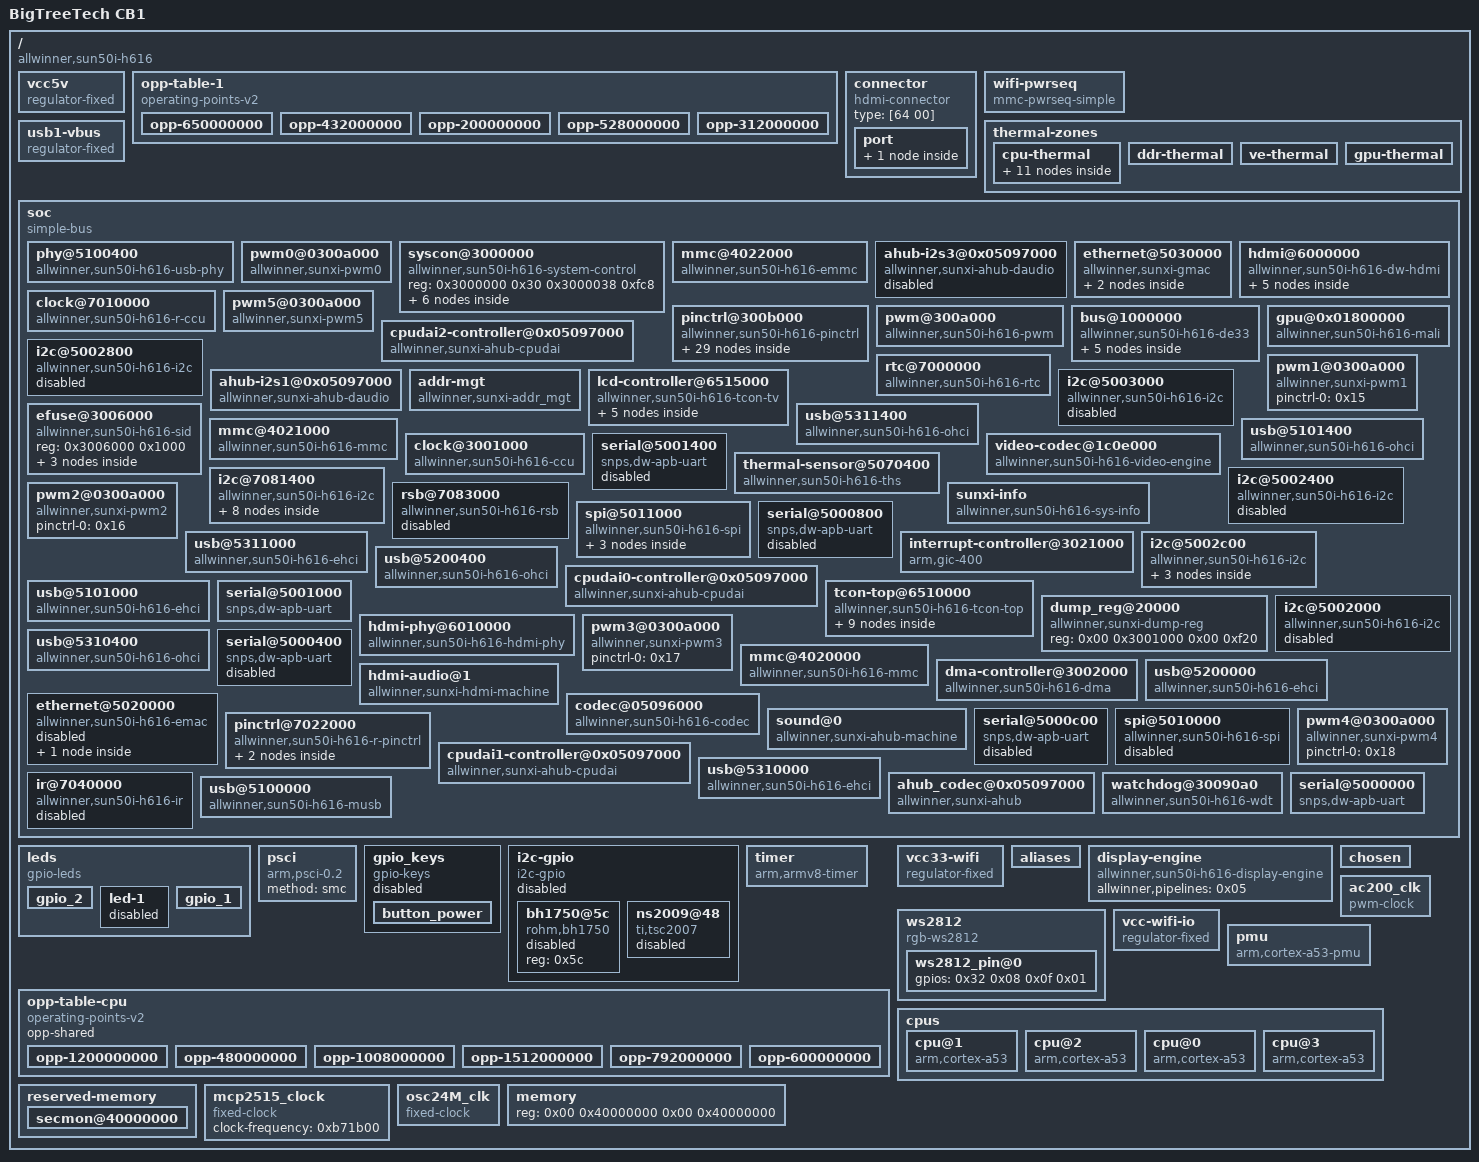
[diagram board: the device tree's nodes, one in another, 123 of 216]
/dts-v1/;

/ {
	#address-cells = <0x02>;
	model = "BigTreeTech CB1";
	serial-number = "32c05000bf61e8cd";
	#size-cells = <0x02>;
	interrupt-parent = <0x01>;
	compatible = "allwinner,sun50i-h616";

	vcc5v {
		regulator-max-microvolt = <0x4c4b40>;
		regulator-always-on;
		regulator-min-microvolt = <0x4c4b40>;
		regulator-name = "vcc-5v";
		compatible = "regulator-fixed";
		phandle = <0x53>;
	};

	opp-table-1 {
		compatible = "operating-points-v2";
		phandle = <0x45>;

		opp-650000000 {
			opp-microvolt = <0xf1b30>;
			opp-hz = <0x00 0x26be3680>;
		};

		opp-432000000 {
			opp-microvolt = <0xf1b30>;
			opp-hz = <0x00 0x19bfcc00>;
		};

		opp-200000000 {
			opp-microvolt = <0xf1b30>;
			opp-hz = <0x00 0xbebc200>;
		};

		opp-528000000 {
			opp-microvolt = <0xf1b30>;
			opp-hz = <0x00 0x1f78a400>;
		};

		opp-312000000 {
			opp-microvolt = <0xf1b30>;
			opp-hz = <0x00 0x1298be00>;
		};
	};

	connector {
		type = [64 00];
		compatible = "hdmi-connector";

		port {

			endpoint {
				remote-endpoint = <0x52>;
				phandle = <0x3d>;
			};
		};
	};

	wifi-pwrseq {
		clock-names = "osc32k-out";
		clocks = <0x0e 0x01>;
		reset-gpios = <0x32 0x06 0x12 0x01>;
		compatible = "mmc-pwrseq-simple";
		post-power-on-delay-ms = <0xc8>;
		phandle = <0x1f>;
	};

	thermal-zones {

		cpu-thermal {
			polling-delay = <0x3e8>;
			polling-delay-passive = <0x1f4>;
			thermal-sensors = <0x4d 0x02>;

			trips {

				cpu_crit {
					temperature = <0x19a28>;
					hysteresis = <0x7d0>;
					type = "critical";
					phandle = <0xa2>;
				};

				cpu_very_hot {
					temperature = <0x15f90>;
					hysteresis = <0x7d0>;
					type = "passive";
					phandle = <0x51>;
				};

				cpu_hot_pre {
					temperature = <0x13880>;
					hysteresis = <0x7d0>;
					type = "passive";
					phandle = <0x4f>;
				};

				cpu_hot {
					temperature = <0x14c08>;
					hysteresis = <0x7d0>;
					type = "passive";
					phandle = <0x50>;
				};

				cpu_warm {
					temperature = <0x124f8>;
					hysteresis = <0x7d0>;
					type = "passive";
					phandle = <0x4e>;
				};
			};

			cooling-maps {

				cpu_very_hot_limit_cpu {
					trip = <0x51>;
					cooling-device = <0x06 0x05 0xffffffff>;
				};

				cpu_warm_limit_cpu {
					trip = <0x4e>;
					cooling-device = <0x06 0xffffffff 0x02>;
				};

				cpu_hot_limit_cpu {
					trip = <0x50>;
					cooling-device = <0x06 0x03 0x04>;
				};

				cpu_hot_pre_limit_cpu {
					trip = <0x4f>;
					cooling-device = <0x06 0x02 0x03>;
				};
			};
		};

		ddr-thermal {
			polling-delay = <0x00>;
			polling-delay-passive = <0x00>;
			thermal-sensors = <0x4d 0x03>;
		};

		ve-thermal {
			polling-delay = <0x00>;
			polling-delay-passive = <0x00>;
			thermal-sensors = <0x4d 0x01>;
		};

		gpu-thermal {
			polling-delay = <0x00>;
			polling-delay-passive = <0x00>;
			thermal-sensors = <0x4d 0x00>;
		};
	};

	usb1-vbus {
		regulator-max-microvolt = <0x4c4b40>;
		enable-active-high;
		regulator-min-microvolt = <0x4c4b40>;
		regulator-name = "usb1-vbus";
		compatible = "regulator-fixed";
		status = "okay";
		phandle = <0x39>;
		vin-supply = <0x53>;
	};

	soc {
		#address-cells = <0x01>;
		#size-cells = <0x01>;
		compatible = "simple-bus";
		ranges = <0x00 0x00 0x00 0x40000000>;

		phy@5100400 {
			usb1_vbus-supply = <0x39>;
			clock-names = "usb0_phy\0usb1_phy\0usb2_phy\0usb3_phy\0pmu2_clk";
			reg-names = "phy_ctrl\0pmu0\0pmu1\0pmu2\0pmu3";
			resets = <0x02 0x26 0x02 0x27 0x02 0x28 0x02 0x29>;
			clocks = <0x02 0x61 0x02 0x63 0x02 0x65 0x02 0x67 0x02 0x6e>;
			#phy-cells = <0x01>;
			compatible = "allwinner,sun50i-h616-usb-phy";
			status = "okay";
			reg = <0x5100400 0x24 0x5101800 0x14 0x5200800 0x14 0x5310800 0x14 0x5311800 0x14>;
			phandle = <0x38>;
			reset-names = "usb0_reset\0usb1_reset\0usb2_reset\0usb3_reset";
		};

		pwm0@0300a000 {
			compatible = "allwinner,sunxi-pwm0";
			phandle = <0x0f>;
		};

		syscon@3000000 {
			#address-cells = <0x01>;
			#size-cells = <0x01>;
			compatible = "allwinner,sun50i-h616-system-control";
			ranges;
			reg = <0x3000000 0x30 0x3000038 0xfc8>;
			phandle = <0x35>;

			sram@1a00000 {
				#address-cells = <0x01>;
				#size-cells = <0x01>;
				compatible = "mmio-sram";
				ranges = <0x00 0x1a00000 0x200000>;
				reg = <0x1a00000 0x200000>;
				phandle = <0x5b>;

				sram-section@0 {
					compatible = "allwinner,sun50i-h616-sram-c1";
					reg = <0x00 0x200000>;
					phandle = <0x43>;
				};
			};

			sram@100000 {
				#address-cells = <0x01>;
				#size-cells = <0x01>;
				compatible = "mmio-sram";
				ranges = <0x00 0x100000 0x18000>;
				reg = <0x100000 0x18000>;
				phandle = <0x58>;

				scpi-sram@17c00 {
					compatible = "arm,scp-shmem";
					reg = <0x17c00 0x200>;
					phandle = <0x59>;
				};
			};

			sram@28000 {
				#address-cells = <0x01>;
				#size-cells = <0x01>;
				compatible = "mmio-sram";
				ranges = <0x00 0x28000 0x30000>;
				reg = <0x28000 0x30000>;
				phandle = <0x5a>;

				sram-section@0 {
					compatible = "allwinner,sun50i-h616-sram-c\0allwinner,sun50i-a64-sram-c";
					reg = <0x00 0x1e000>;
					phandle = <0x0a>;
				};
			};
		};

		mmc@4022000 {
			mmc-ddr-3_3v;
			pinctrl-names = "default";
			#address-cells = <0x01>;
			pinctrl-0 = <0x20>;
			clock-names = "ahb\0mmc";
			cap-sd-highspeed;
			bus-width = <0x08>;
			non-removable;
			resets = <0x02 0x10>;
			cap-sdio-irq;
			interrupts = <0x00 0x25 0x04>;
			clocks = <0x02 0x41 0x02 0x3e>;
			#size-cells = <0x00>;
			vmmc-supply = <0x1b>;
			no-1-8-v;
			mmc-ddr-1_8v;
			compatible = "allwinner,sun50i-h616-emmc\0allwinner,sun50i-a100-emmc";
			status = "okay";
			reg = <0x4022000 0x1000>;
			phandle = <0x69>;
			max-frequency = <0x2625a00>;
			cap-mmc-highspeed;
			reset-names = "ahb";
		};

		ahub-i2s3@0x05097000 {
			pinctrl-names = "default";
			daudio_master = <0x04>;
			pinctrl-0 = <0x26>;
			clock-names = "apb\0audio-codec-1x\0audio-codec-4x\0audio-hub";
			signal_inversion = <0x01>;
			mclk_div = <0x04>;
			clocks = <0x02 0x5f 0x02 0x5b 0x02 0x5c 0x02 0x5e>;
			pinconfig = <0x01>;
			frametype = <0x00>;
			compatible = "allwinner,sunxi-ahub-daudio";
			audio_format = <0x01>;
			slot_width_select = <0x20>;
			status = "disabled";
			tdm_num = <0x03>;
			reg = <0x5097000 0xadf>;
			phandle = <0x6c>;
			tdm_config = <0x01>;
			pcm_lrck_period = <0x20>;
		};

		ethernet@5030000 {
			rx-delay = <0x1f>;
			gmac-power1;
			pinctrl-names = "default";
			phy-supply = <0x1b>;
			phy-mode = "rmii";
			phy-rst;
			tx-delay = <0x07>;
			pinctrl-0 = <0x36>;
			clock-names = "bus-emac1\0emac-25m";
			reg-names = "gmac1_reg\0ephy_reg";
			local-mac-address = [02 00 bf 61 e8 cd];
			resets = <0x02 0x1f>;
			interrupts = <0x00 0x0f 0x04>;
			clocks = <0x02 0x53 0x02 0x51>;
			gmac-power2;
			gmac-power0;
			compatible = "allwinner,sunxi-gmac";
			status = "okay";
			interrupt-names = "gmacirq";
			reg = <0x5030000 0x10000 0x3000034 0x04>;
			phandle = <0x81>;
			allwinner,tx-delay-ps = <0x2bc>;
			phy-handle = <0x37>;
			reset-names = "stmmaceth";
			allwinner,rx-delay-ps = <0xc1c>;

			mdio {
				#address-cells = <0x01>;
				#size-cells = <0x00>;
				compatible = "ethernet-phy-ieee802.3-c22";
				phandle = <0x82>;

				ethernet-phy@1 {
					compatible = "ethernet-phy-ieee802.3-c22";
					reg = <0x01>;
					phandle = <0x37>;
				};
			};
		};

		hdmi@6000000 {
			reg-io-width = <0x01>;
			phy-names = "phy";
			clock-names = "iahb\0isfr\0tmds\0cec\0hdcp\0hdcp-bus";
			hvcc-supply = <0x3b>;
			resets = <0x02 0x33 0x02 0x3a>;
			interrupts = <0x00 0x3f 0x04>;
			clocks = <0x02 0x75 0x02 0x73 0x02 0x72 0x02 0x74 0x02 0x7e 0x02 0x7f>;
			drive-strength = <0x0a>;
			#sound-dai-cells = <0x00>;
			compatible = "allwinner,sun50i-h616-dw-hdmi";
			status = "okay";
			phys = <0x3a>;
			reg = <0x6000000 0x10000>;
			phandle = <0x8c>;
			reset-names = "ctrl\0hdcp";

			ports {
				#address-cells = <0x01>;
				#size-cells = <0x00>;

				port@0 {
					reg = <0x00>;
					phandle = <0x8d>;

					endpoint {
						remote-endpoint = <0x3c>;
						phandle = <0x42>;
					};
				};

				port@1 {
					reg = <0x01>;
					phandle = <0x8e>;

					endpoint {
						remote-endpoint = <0x3d>;
						phandle = <0x52>;
					};
				};
			};
		};

		clock@7010000 {
			#reset-cells = <0x01>;
			clock-names = "hosc\0losc\0iosc\0pll-periph";
			clocks = <0x0d 0x0e 0x00 0x0e 0x02 0x02 0x04>;
			#clock-cells = <0x01>;
			compatible = "allwinner,sun50i-h616-r-ccu";
			reg = <0x7010000 0x210>;
			phandle = <0x49>;
		};

		pinctrl@300b000 {
			clock-names = "apb\0hosc\0losc";
			gpio-controller;
			interrupts = <0x00 0x33 0x04 0x00 0x34 0x04 0x00 0x35 0x04 0x00 0x2b 0x04 0x00 0x36 0x04 0x00 0x37 0x04 0x00 0x38 0x04 0x00 0x39 0x04>;
			clocks = <0x02 0x1a 0x0d 0x0e 0x00>;
			compatible = "allwinner,sun50i-h616-pinctrl";
			#interrupt-cells = <0x03>;
			reg = <0x300b000 0x400>;
			phandle = <0x32>;
			#gpio-cells = <0x03>;
			interrupt-controller;

			pwm4-pin {
				function = "pwm4";
				pins = "PH1";
				phandle = <0x18>;
			};

			uart4-ph-pins {
				function = "uart4";
				pins = "PI13\0PI14";
				phandle = <0x28>;
			};

			spi1-cs-pin {
				function = "spi1";
				pins = "PH9";
				phandle = <0x61>;
			};

			i2c4-pins {
				function = "i2c4";
				pins = "PH6\0PH7";
				phandle = <0x2f>;
			};

			rmii-pins {
				function = "emac1";
				pins = "PA0\0PA1\0PA2\0PA3\0PA4\0PA5\0PA6\0PA7\0PA8\0PA9";
				drive-strength = <0x28>;
				phandle = <0x36>;
			};

			pwm1-pin {
				function = "pwm1";
				pins = "PH3";
				phandle = <0x15>;
			};

			pwm5-pin {
				function = "pwm5";
				pins = "PA12";
				phandle = <0x19>;
			};

			mmc2-pins {
				function = "mmc2";
				pins = "PC0\0PC1\0PC5\0PC6\0PC8\0PC9\0PC10\0PC11\0PC13\0PC14\0PC15\0PC16";
				drive-strength = <0x1e>;
				phandle = <0x20>;
				bias-pull-up;
			};

			twi3-pins {
				function = "twi3";
				pins = "PA10\0PA11";
				phandle = <0x2c>;
				bias-pull-up;
			};

			i2c3-pins {
				function = "i2c3";
				pins = "PH4\0PH5";
				phandle = <0x60>;
			};

			can0_pin_irq {
				function = "irq";
				pins = "PI3";
				phandle = <0x34>;
				bias-pull-up;
			};

			ir-rx-pin {
				function = "ir_rx";
				pins = "PH10";
				phandle = <0x4a>;
			};

			mmc1-pins {
				function = "mmc1";
				pins = "PG0\0PG1\0PG2\0PG3\0PG4\0PG5";
				drive-strength = <0x28>;
				phandle = <0x1c>;
				bias-pull-up;
			};

			i2c2-pins {
				function = "i2c2";
				pins = "PH2\0PH3";
				phandle = <0x2b>;
			};

			pwm2-pin {
				function = "pwm2";
				pins = "PH2";
				phandle = <0x16>;
			};

			uart1-rts-cts-pins {
				function = "uart1";
				pins = "PG8\0PG9";
				phandle = <0x63>;
			};

			rgmii-pins {
				function = "emac0";
				pins = "PI0\0PI1\0PI2\0PI3\0PI4\0PI5\0PI7\0PI8\0PI9\0PI10\0PI11\0PI12\0PI13\0PI14\0PI15\0PI16";
				drive-strength = <0x28>;
				phandle = <0x5f>;
			};

			mmc0-pins {
				function = "mmc0";
				pins = "PF0\0PF1\0PF2\0PF3\0PF4\0PF5";
				drive-strength = <0x28>;
				phandle = <0x1a>;
				bias-pull-up;
			};

			i2c1-pins {
				function = "i2c1";
				pins = "PH0\0PH1";
				phandle = <0x2a>;
			};

			uart5-ph-pins {
				function = "uart5";
				pins = "PH2\0PH3";
				phandle = <0x66>;
			};

			spi1-pins {
				function = "spi1";
				pins = "PH6\0PH7\0PH8";
				phandle = <0x31>;
			};

			i2s3-pins {
				function = "i2s3";
				pins = "PH5\0PH6\0PH7\0PH8\0PH9";
				phandle = <0x26>;
			};

			pwm3-pin {
				function = "pwm3";
				pins = "PH0";
				phandle = <0x17>;
			};

			i2c0-pins {
				function = "i2c0";
				pins = "PI5\0PI6";
				phandle = <0x29>;
				bias-pull-up;
			};

			uart0-ph-pins {
				function = "uart0";
				pins = "PH0\0PH1";
				phandle = <0x27>;
			};

			uart2-rts-cts-pins {
				function = "uart2";
				pins = "PH7\0PH8";
				phandle = <0x65>;
			};

			uart1-pins {
				function = "uart1";
				pins = "PG6\0PG7";
				phandle = <0x62>;
			};

			spi0-pins {
				function = "spi0";
				pins = "PC0\0PC2\0PC4";
				phandle = <0x30>;
			};

			uart2-ph-pins {
				function = "uart2";
				pins = "PH5\0PH6";
				phandle = <0x64>;
			};
		};

		pwm5@0300a000 {
			pinctrl-names = "default";
			clk_bypass_output = <0x01>;
			pinctrl-0 = <0x19>;
			compatible = "allwinner,sunxi-pwm5";
			phandle = <0x14>;
		};

		pwm@300a000 {
			clock-names = "mod\0bus";
			resets = <0x02 0x0a>;
			clocks = <0x0d 0x02 0x2f>;
			pwm-number = <0x06>;
			#pwm-cells = <0x03>;
			compatible = "allwinner,sun50i-h616-pwm";
			status = "okay";
			reg = <0x300a000 0x400>;
			phandle = <0x54>;
			pwm-base = <0x00>;
			sunxi-pwms = <0x0f 0x10 0x11 0x12 0x13 0x14>;
		};

		bus@1000000 {
			#address-cells = <0x01>;
			allwinner,sram = <0x0a 0x01>;
			#size-cells = <0x01>;
			compatible = "allwinner,sun50i-h616-de33\0allwinner,sun50i-a64-de2";
			ranges = <0x00 0x1000000 0x400000>;
			reg = <0x1000000 0x400000>;

			mixer@100000 {
				clock-names = "bus\0mod";
				resets = <0x0b 0x00>;
				clocks = <0x0b 0x00 0x0b 0x06>;
				compatible = "allwinner,sun50i-h616-de33-mixer-0";
				reg = <0x100000 0x100000 0x8100 0x40 0x280000 0x20000>;
				phandle = <0x05>;

				ports {
					#address-cells = <0x01>;
					#size-cells = <0x00>;

					port@1 {
						reg = <0x01>;
						phandle = <0x57>;

						endpoint {
							remote-endpoint = <0x0c>;
							phandle = <0x3f>;
						};
					};
				};
			};

			clock@8000 {
				#reset-cells = <0x01>;
				clock-names = "mod\0bus";
				resets = <0x02 0x01>;
				clocks = <0x02 0x1d 0x02 0x1e>;
				#clock-cells = <0x01>;
				compatible = "allwinner,sun50i-h616-de33-clk";
				reg = <0x8000 0x100>;
				phandle = <0x0b>;
			};
		};

		cpudai2-controller@0x05097000 {
			id = <0x02>;
			dma-names = "rx\0tx";
			compatible = "allwinner,sunxi-ahub-cpudai";
			status = "okay";
			reg = <0x5097000 0xadf>;
			phandle = <0x24>;
			dmas = <0x21 0x05 0x21 0x05>;
		};

		gpu@0x01800000 {
			mali-supply = <0x44>;
			clock-names = "core\0bus";
			resets = <0x02 0x03>;
			interrupts = <0x00 0x5f 0x04 0x00 0x60 0x04 0x00 0x61 0x04>;
			clocks = <0x02 0x23 0x02 0x24>;
			interrupt-parent = <0x01>;
			compatible = "allwinner,sun50i-h616-mali\0arm,mali-bifrost";
			status = "okay";
			interrupt-names = "job\0mmu\0gpu";
			reg = <0x1800000 0x40000>;
			phandle = <0x94>;
			operating-points-v2 = <0x45>;
			#cooling-cells = <0x02>;
		};

		i2c@5002800 {
			pinctrl-names = "default";
			#address-cells = <0x01>;
			pinctrl-0 = <0x2b>;
			resets = <0x02 0x19>;
			interrupts = <0x00 0x08 0x04>;
			clocks = <0x02 0x4a>;
			#size-cells = <0x00>;
			compatible = "allwinner,sun50i-h616-i2c\0allwinner,sun6i-a31-i2c";
			status = "disabled";
			reg = <0x5002800 0x400>;
			phandle = <0x75>;
		};

		ahub-i2s1@0x05097000 {
			daudio_master = <0x04>;
			clock-names = "apb\0audio-codec-1x\0audio-codec-4x\0audio-hub";
			signal_inversion = <0x01>;
			mclk_div = <0x01>;
			clocks = <0x02 0x5f 0x02 0x5b 0x02 0x5c 0x02 0x5e>;
			pinconfig = <0x00>;
			#sound-dai-cells = <0x00>;
			frametype = <0x00>;
			compatible = "allwinner,sunxi-ahub-daudio";
			audio_format = <0x01>;
			slot_width_select = <0x20>;
			status = "okay";
			tdm_num = <0x01>;
			reg = <0x5097000 0xadf>;
			phandle = <0x3e>;
			tdm_config = <0x01>;
			pcm_lrck_period = <0x20>;
		};

		rtc@7000000 {
			clock-output-names = "osc32k\0osc32k-out\0iosc";
			interrupts = <0x00 0x65 0x04 0x00 0x66 0x04>;
			#clock-cells = <0x01>;
			compatible = "allwinner,sun50i-h616-rtc\0allwinner,sun50i-h6-rtc";
			reg = <0x7000000 0x400>;
			phandle = <0x0e>;
		};

		pwm1@0300a000 {
			pinctrl-names = "default";
			pinctrl-0 = <0x15>;
			compatible = "allwinner,sunxi-pwm1";
			phandle = <0x10>;
		};

		addr-mgt {
			compatible = "allwinner,sunxi-addr_mgt";
			status = "okay";
			type_addr_eth = <0x02>;
			type_addr_wifi = <0x02>;
			phandle = <0xa1>;
			type_addr_bt = <0x02>;
		};

		lcd-controller@6515000 {
			clock-names = "ahb\0tcon-ch1";
			resets = <0x02 0x36>;
			interrupts = <0x00 0x42 0x04>;
			clocks = <0x02 0x79 0x46 0x00>;
			compatible = "allwinner,sun50i-h616-tcon-tv";
			reg = <0x6515000 0x1000>;
			phandle = <0x95>;
			reset-names = "lcd";

			ports {
				#address-cells = <0x01>;
				#size-cells = <0x00>;

				port@0 {
					reg = <0x00>;
					phandle = <0x96>;

					endpoint {
						remote-endpoint = <0x47>;
						phandle = <0x40>;
					};
				};

				port@1 {
					#address-cells = <0x01>;
					#size-cells = <0x00>;
					reg = <0x01>;
					phandle = <0x97>;

					endpoint@1 {
						remote-endpoint = <0x48>;
						reg = <0x01>;
						phandle = <0x41>;
					};
				};
			};
		};

		i2c@5003000 {
			pinctrl-names = "default";
			#address-cells = <0x01>;
			pinctrl-0 = <0x2f>;
			resets = <0x02 0x1b>;
			interrupts = <0x00 0x0a 0x04>;
			clocks = <0x02 0x4c>;
			#size-cells = <0x00>;
			compatible = "allwinner,sun50i-h616-i2c\0allwinner,sun6i-a31-i2c";
			status = "disabled";
			reg = <0x5003000 0x400>;
			phandle = <0x7a>;
		};

		usb@5311400 {
			phy-names = "usb";
			resets = <0x02 0x2d 0x02 0x28>;
			interrupts = <0x00 0x21 0x04>;
			clocks = <0x02 0x6b 0x02 0x66 0x02 0x65>;
			compatible = "allwinner,sun50i-h616-ohci\0generic-ohci";
			status = "okay";
			phys = <0x38 0x03>;
			reg = <0x5311400 0x100>;
			phandle = <0x8b>;
		};

		efuse@3006000 {
			#address-cells = <0x01>;
			#size-cells = <0x01>;
			compatible = "allwinner,sun50i-h616-sid";
			reg = <0x3006000 0x1000>;
			phandle = <0x5c>;

			thermal-sensor-calibration@14 {
				reg = <0x14 0x08>;
				phandle = <0x4c>;
			};

			cpu-speed-grade@00 {
				reg = <0x00 0x02>;
				phandle = <0x5d>;
			};

			ephy-calibration@2c {
				reg = <0x2c 0x04>;
				phandle = <0x2e>;
			};
		};

		mmc@4021000 {
			mmc-ddr-3_3v;
			pinctrl-names = "default";
			#address-cells = <0x01>;
			pinctrl-0 = <0x1c>;
			clock-names = "ahb\0mmc";
			cap-sd-highspeed;
			vqmmc-supply = <0x1e>;
			bus-width = <0x04>;
			non-removable;
			resets = <0x02 0x0f>;
			cap-sdio-irq;
			interrupts = <0x00 0x24 0x04>;
			clocks = <0x02 0x40 0x02 0x3d>;
			#size-cells = <0x00>;
			vmmc-supply = <0x1d>;
			mmc-ddr-1_8v;
			compatible = "allwinner,sun50i-h616-mmc\0allwinner,sun50i-a100-mmc";
			status = "okay";
			mmc-pwrseq = <0x1f>;
			reg = <0x4021000 0x1000>;
			phandle = <0x68>;
			max-frequency = <0x17d7840>;
			cap-mmc-highspeed;
			reset-names = "ahb";
		};

		usb@5101400 {
			phy-names = "usb";
			resets = <0x02 0x2a 0x02 0x28>;
			interrupts = <0x00 0x1b 0x04>;
			clocks = <0x02 0x68 0x02 0x60 0x02 0x65>;
			compatible = "allwinner,sun50i-h616-ohci\0generic-ohci";
			status = "okay";
			phys = <0x38 0x00>;
			reg = <0x5101400 0x100>;
			phandle = <0x85>;
		};

		clock@3001000 {
			#reset-cells = <0x01>;
			clock-names = "hosc\0losc\0iosc";
			clocks = <0x0d 0x0e 0x00 0x0e 0x02>;
			#clock-cells = <0x01>;
			compatible = "allwinner,sun50i-h616-ccu";
			reg = <0x3001000 0x1000>;
			phandle = <0x02>;
		};

		serial@5001400 {
			reg-io-width = <0x04>;
			resets = <0x02 0x16>;
			interrupts = <0x00 0x05 0x04>;
			clocks = <0x02 0x47>;
			compatible = "snps,dw-apb-uart";
			status = "disabled";
			reg = <0x5001400 0x400>;
			phandle = <0x72>;
			reg-shift = <0x02>;
		};

		video-codec@1c0e000 {
			clock-names = "ahb\0mod\0ram";
			allwinner,sram = <0x43 0x01>;
			resets = <0x02 0x05>;
			interrupts = <0x00 0x5d 0x04>;
			clocks = <0x02 0x29 0x02 0x28 0x02 0x33>;
			compatible = "allwinner,sun50i-h616-video-engine";
			reg = <0x1c0e000 0x2000>;
		};

		thermal-sensor@5070400 {
			nvmem-cells = <0x4c>;
			clock-names = "bus";
			resets = <0x02 0x21>;
			interrupts = <0x00 0x13 0x04>;
			clocks = <0x02 0x56>;
			#thermal-sensor-cells = <0x01>;
			compatible = "allwinner,sun50i-h616-ths";
			nvmem-cell-names = "calibration";
			reg = <0x5070400 0x400>;
			phandle = <0x4d>;
		};

		i2c@7081400 {
			#address-cells = <0x01>;
			resets = <0x49 0x04>;
			interrupts = <0x00 0x69 0x04>;
			clocks = <0x49 0x08>;
			#size-cells = <0x00>;
			compatible = "allwinner,sun50i-h616-i2c\0allwinner,sun6i-a31-i2c";
			status = "okay";
			reg = <0x7081400 0x400>;
			phandle = <0x9b>;

			pmic@36 {
				wakeup-source;
				compatible = "x-powers,axp1530";
				status = "okay";
				reg = <0x36>;
				phandle = <0x9c>;

				regulators {

					dcdc3 {
						regulator-max-microvolt = <0x16e360>;
						regulator-step-delay-us = <0x19>;
						regulator-always-on;
						regulator-min-microvolt = <0x149970>;
						regulator-name = "axp1530-dcdc3";
						regulator-final-delay-us = <0x32>;
						phandle = <0x9e>;
					};

					dcdc1 {
						regulator-max-microvolt = <0xf1b30>;
						regulator-step-delay-us = <0x19>;
						regulator-always-on;
						regulator-min-microvolt = <0xc5c10>;
						regulator-name = "axp1530-dcdc1";
						regulator-final-delay-us = <0x32>;
						phandle = <0x44>;
					};

					ldo2 {
						regulator-max-microvolt = <0x325aa0>;
						regulator-step-delay-us = <0x19>;
						regulator-always-on;
						regulator-min-microvolt = <0x325aa0>;
						regulator-name = "axp1530-dldo1";
						regulator-final-delay-us = <0x32>;
						phandle = <0x1b>;
					};

					dcdc2 {
						regulator-max-microvolt = <0x10c8e0>;
						regulator-step-delay-us = <0x19>;
						regulator-always-on;
						regulator-min-microvolt = <0xc5c10>;
						regulator-name = "axp1530-dcdc2";
						regulator-ramp-delay = <0xc8>;
						regulator-final-delay-us = <0x32>;
						phandle = <0x04>;
					};

					ldo1 {
						regulator-max-microvolt = <0x1b7740>;
						regulator-step-delay-us = <0x19>;
						regulator-always-on;
						regulator-min-microvolt = <0x1b7740>;
						regulator-name = "axp1530-aldo1";
						regulator-final-delay-us = <0x32>;
						phandle = <0x3b>;
					};
				};

				standby_param {
					phandle = <0x9d>;
					vcc-dram = <0x04>;
				};
			};
		};

		i2c@5002400 {
			pinctrl-names = "default";
			#address-cells = <0x01>;
			pinctrl-0 = <0x2a>;
			resets = <0x02 0x18>;
			interrupts = <0x00 0x07 0x04>;
			clocks = <0x02 0x49>;
			#size-cells = <0x00>;
			compatible = "allwinner,sun50i-h616-i2c\0allwinner,sun6i-a31-i2c";
			status = "disabled";
			reg = <0x5002400 0x400>;
			phandle = <0x74>;
		};

		pwm2@0300a000 {
			pinctrl-names = "default";
			pinctrl-0 = <0x16>;
			compatible = "allwinner,sunxi-pwm2";
			phandle = <0x11>;
		};

		rsb@7083000 {
			pinctrl-names = "default";
			#address-cells = <0x01>;
			pinctrl-0 = <0x4b>;
			resets = <0x49 0x07>;
			interrupts = <0x00 0x6d 0x04>;
			clocks = <0x49 0x0d>;
			#size-cells = <0x00>;
			clock-frequency = <0x2dc6c0>;
			compatible = "allwinner,sun50i-h616-rsb\0allwinner,sun8i-a23-rsb";
			status = "disabled";
			reg = <0x7083000 0x400>;
			phandle = <0x9f>;
		};

		sunxi-info {
			compatible = "allwinner,sun50i-h616-sys-info";
			status = "okay";
		};

		spi@5011000 {
			pinctrl-names = "default";
			#address-cells = <0x01>;
			pinctrl-0 = <0x31>;
			clock-names = "ahb\0mod";
			resets = <0x02 0x1d>;
			interrupts = <0x00 0x0d 0x04>;
			clocks = <0x02 0x50 0x02 0x4e>;
			#size-cells = <0x00>;
			dma-names = "rx\0tx";
			compatible = "allwinner,sun50i-h616-spi\0allwinner,sun8i-h3-spi";
			status = "okay";
			reg = <0x5011000 0x1000>;
			phandle = <0x7c>;
			dmas = <0x21 0x17 0x21 0x17>;
			cs-gpios = <0x32 0x08 0x05 0x00 0x32 0x08 0x0e 0x00 0x32 0x08 0x07 0x00>;

			st7796@1 {
				rotate = <0x00>;
				bgr;
				height = <0x140>;
				txbuflen = <0x4b000>;
				width = <0x1e0>;
				regwidth = <0x08>;
				bpp = <0x18>;
				spi-max-frequency = <0xbebc20>;
				spi-cpol;
				fps = <0x3c>;
				compatible = "sitronix,st7796";
				dc-gpios = <0x32 0x08 0x0f 0x00>;
				buswidth = <0x08>;
				status = "disabled";
				spi-cpha;
				reg = <0x01>;
				phandle = <0x7e>;
				debug = <0x00>;
			};

			mcp2515@0 {
				pinctrl-names = "default";
				pinctrl-0 = <0x34>;
				interrupts = <0x08 0x03 0x08>;
				clocks = <0x33>;
				spi-max-frequency = <0xbebc20>;
				xceiver-supply = <0x1d>;
				interrupt-parent = <0x32>;
				vdd-supply = <0x1d>;
				compatible = "microchip,mcp2515";
				status = "disabled";
				reg = <0x00>;
				phandle = <0x7d>;
			};

			spidev@1 {
				spi-max-frequency = <0xf4240>;
				compatible = "rohm,dh2228fv";
				status = "okay";
				reg = <0x01>;
				phandle = <0xa7>;
			};
		};

		serial@5000800 {
			reg-io-width = <0x04>;
			resets = <0x02 0x13>;
			interrupts = <0x00 0x02 0x04>;
			clocks = <0x02 0x44>;
			compatible = "snps,dw-apb-uart";
			status = "disabled";
			reg = <0x5000800 0x400>;
			phandle = <0x6f>;
			reg-shift = <0x02>;
		};

		interrupt-controller@3021000 {
			interrupts = <0x01 0x09 0xf04>;
			compatible = "arm,gic-400";
			#interrupt-cells = <0x03>;
			reg = <0x3021000 0x1000 0x3022000 0x2000 0x3024000 0x2000 0x3026000 0x2000>;
			phandle = <0x01>;
			interrupt-controller;
		};

		usb@5311000 {
			phy-names = "usb";
			resets = <0x02 0x2d 0x02 0x31 0x02 0x28>;
			interrupts = <0x00 0x20 0x04>;
			clocks = <0x02 0x6b 0x02 0x6f 0x02 0x66 0x02 0x65>;
			compatible = "allwinner,sun50i-h616-ehci\0generic-ehci";
			status = "okay";
			phys = <0x38 0x03>;
			reg = <0x5311000 0x100>;
			phandle = <0x8a>;
		};

		i2c@5002c00 {
			pinctrl-names = "default";
			#address-cells = <0x01>;
			pinctrl-0 = <0x2c>;
			resets = <0x02 0x1a>;
			interrupts = <0x00 0x09 0x04>;
			clocks = <0x02 0x4b>;
			#size-cells = <0x00>;
			compatible = "allwinner,sun50i-h616-i2c\0allwinner,sun6i-a31-i2c";
			status = "okay";
			reg = <0x5002c00 0x400>;
			phandle = <0x76>;

			mfd@10 {
				nvmem-cells = <0x2e>;
				clocks = <0x2d>;
				compatible = "x-powers,ac200";
				nvmem-cell-names = "calibration";
				reg = <0x10>;
				phandle = <0x77>;

				codec {
					#sound-dai-cells = <0x00>;
					compatible = "x-powers,ac200-codec";
					status = "disabled";
					phandle = <0x79>;
				};

				phy {
					compatible = "x-powers,ac200-ephy";
					status = "okay";
					phandle = <0x78>;
				};
			};
		};

		usb@5200400 {
			phy-names = "usb";
			resets = <0x02 0x2b 0x02 0x28>;
			interrupts = <0x00 0x1d 0x04>;
			clocks = <0x02 0x69 0x02 0x62 0x02 0x65>;
			compatible = "allwinner,sun50i-h616-ohci\0generic-ohci";
			status = "okay";
			phys = <0x38 0x01>;
			reg = <0x5200400 0x100>;
			phandle = <0x87>;
		};

		cpudai0-controller@0x05097000 {
			id = <0x00>;
			dma-names = "rx\0tx";
			compatible = "allwinner,sunxi-ahub-cpudai";
			status = "okay";
			reg = <0x5097000 0xadf>;
			phandle = <0x22>;
			dmas = <0x21 0x03 0x21 0x03>;
		};

		usb@5101000 {
			phy-names = "usb";
			resets = <0x02 0x2a 0x02 0x2e 0x02 0x28>;
			interrupts = <0x00 0x1a 0x04>;
			clocks = <0x02 0x68 0x02 0x6c 0x02 0x60 0x02 0x65>;
			compatible = "allwinner,sun50i-h616-ehci\0generic-ehci";
			status = "okay";
			phys = <0x38 0x00>;
			reg = <0x5101000 0x100>;
			phandle = <0x84>;
		};

		tcon-top@6510000 {
			clock-output-names = "tcon-top-tv0";
			clock-names = "bus\0tcon-tv0";
			resets = <0x02 0x35>;
			clocks = <0x02 0x76 0x02 0x77>;
			#clock-cells = <0x01>;
			compatible = "allwinner,sun50i-h616-tcon-top";
			reg = <0x6510000 0x1000>;
			phandle = <0x46>;

			ports {
				#address-cells = <0x01>;
				#size-cells = <0x00>;

				port@0 {
					#address-cells = <0x01>;
					#size-cells = <0x00>;
					reg = <0x00>;
					phandle = <0x90>;

					endpoint@0 {
						remote-endpoint = <0x3f>;
						reg = <0x00>;
						phandle = <0x0c>;
					};
				};

				port@5 {
					reg = <0x05>;
					phandle = <0x93>;

					endpoint {
						remote-endpoint = <0x42>;
						phandle = <0x3c>;
					};
				};

				port@1 {
					#address-cells = <0x01>;
					#size-cells = <0x00>;
					reg = <0x01>;
					phandle = <0x91>;

					endpoint@2 {
						remote-endpoint = <0x40>;
						reg = <0x02>;
						phandle = <0x47>;
					};
				};

				port@4 {
					#address-cells = <0x01>;
					#size-cells = <0x00>;
					reg = <0x04>;
					phandle = <0x92>;

					endpoint@0 {
						remote-endpoint = <0x41>;
						reg = <0x00>;
						phandle = <0x48>;
					};
				};
			};
		};

		serial@5001000 {
			reg-io-width = <0x04>;
			pinctrl-names = "default";
			pinctrl-0 = <0x28>;
			resets = <0x02 0x15>;
			interrupts = <0x00 0x04 0x04>;
			clocks = <0x02 0x46>;
			compatible = "snps,dw-apb-uart";
			status = "okay";
			reg = <0x5001000 0x400>;
			phandle = <0x71>;
			reg-shift = <0x02>;
		};

		dump_reg@20000 {
			compatible = "allwinner,sunxi-dump-reg";
			status = "okay";
			reg = <0x00 0x3001000 0x00 0xf20>;
			phandle = <0xa0>;
		};

		hdmi-phy@6010000 {
			clock-names = "bus\0mod";
			resets = <0x02 0x34>;
			clocks = <0x02 0x75 0x02 0x73>;
			#phy-cells = <0x00>;
			compatible = "allwinner,sun50i-h616-hdmi-phy";
			reg = <0x6010000 0x10000>;
			phandle = <0x3a>;
			reset-names = "phy";
		};

		i2c@5002000 {
			pinctrl-names = "default";
			#address-cells = <0x01>;
			pinctrl-0 = <0x29>;
			resets = <0x02 0x17>;
			interrupts = <0x00 0x06 0x04>;
			clocks = <0x02 0x48>;
			#size-cells = <0x00>;
			compatible = "allwinner,sun50i-h616-i2c\0allwinner,sun6i-a31-i2c";
			status = "disabled";
			reg = <0x5002000 0x400>;
			phandle = <0x73>;
		};

		pwm3@0300a000 {
			pinctrl-names = "default";
			pinctrl-0 = <0x17>;
			compatible = "allwinner,sunxi-pwm3";
			phandle = <0x12>;
		};

		usb@5310400 {
			phy-names = "usb";
			resets = <0x02 0x2c>;
			interrupts = <0x00 0x1f 0x04>;
			clocks = <0x02 0x6a 0x02 0x64>;
			compatible = "allwinner,sun50i-h616-ohci\0generic-ohci";
			status = "okay";
			phys = <0x38 0x02>;
			reg = <0x5310400 0x100>;
			phandle = <0x89>;
		};

		mmc@4020000 {
			mmc-ddr-3_3v;
			pinctrl-names = "default";
			#address-cells = <0x01>;
			pinctrl-0 = <0x1a>;
			clock-names = "ahb\0mmc";
			cap-sd-highspeed;
			bus-width = <0x04>;
			resets = <0x02 0x0e>;
			cap-sdio-irq;
			interrupts = <0x00 0x23 0x04>;
			clocks = <0x02 0x3f 0x02 0x3c>;
			#size-cells = <0x00>;
			vmmc-supply = <0x1b>;
			no-1-8-v;
			mmc-ddr-1_8v;
			compatible = "allwinner,sun50i-h616-mmc\0allwinner,sun50i-a100-mmc";
			status = "okay";
			reg = <0x4020000 0x1000>;
			phandle = <0x67>;
			max-frequency = <0x2faf080>;
			cap-mmc-highspeed;
			reset-names = "ahb";
		};

		serial@5000400 {
			reg-io-width = <0x04>;
			resets = <0x02 0x12>;
			interrupts = <0x00 0x01 0x04>;
			clocks = <0x02 0x43>;
			compatible = "snps,dw-apb-uart";
			status = "disabled";
			reg = <0x5000400 0x400>;
			phandle = <0x6e>;
			reg-shift = <0x02>;
		};

		dma-controller@3002000 {
			clock-names = "bus\0mbus";
			resets = <0x02 0x06>;
			interrupts = <0x00 0x2a 0x04>;
			clocks = <0x02 0x2a 0x02 0x32>;
			dma-requests = <0x31>;
			compatible = "allwinner,sun50i-h616-dma";
			reg = <0x3002000 0x1000>;
			phandle = <0x21>;
			dma-channels = <0x10>;
			#dma-cells = <0x01>;
		};

		usb@5200000 {
			phy-names = "usb";
			resets = <0x02 0x2b 0x02 0x2f 0x02 0x28>;
			interrupts = <0x00 0x1c 0x04>;
			clocks = <0x02 0x69 0x02 0x6d 0x02 0x62 0x02 0x65>;
			compatible = "allwinner,sun50i-h616-ehci\0generic-ehci";
			status = "okay";
			phys = <0x38 0x01>;
			reg = <0x5200000 0x100>;
			phandle = <0x86>;
		};

		hdmi-audio@1 {
			sunxi,snddaudio-codec = "hdmi-audio-codec.4.auto";
			compatible = "allwinner,sunxi-hdmi-machine";
			status = "okay";
			phandle = <0x8f>;
			sunxi,cpudai-controller = <0x3e>;
		};

		ethernet@5020000 {
			syscon = <0x35>;
			clock-names = "stmmaceth";
			resets = <0x02 0x1e>;
			interrupts = <0x00 0x0e 0x04>;
			clocks = <0x02 0x52>;
			compatible = "allwinner,sun50i-h616-emac\0allwinner,sun50i-a64-emac";
			status = "disabled";
			interrupt-names = "macirq";
			reg = <0x5020000 0x10000>;
			phandle = <0x7f>;
			reset-names = "stmmaceth";

			mdio {
				#address-cells = <0x01>;
				#size-cells = <0x00>;
				compatible = "snps,dwmac-mdio";
				phandle = <0x80>;
			};
		};

		codec@05096000 {
			clock-names = "apb\0audio-codec-1x\0audio-codec-4x";
			resets = <0x02 0x24>;
			interrupts = <0x00 0x3a 0x04>;
			clocks = <0x02 0x5d 0x02 0x5b 0x02 0x5c>;
			dma-names = "tx";
			#sound-dai-cells = <0x00>;
			compatible = "allwinner,sun50i-h616-codec";
			status = "okay";
			reg = <0x5096000 0x31c>;
			phandle = <0x6a>;
			dmas = <0x21 0x06>;
			allwinner,audio-routing = "Line Out\0LINEOUT";
		};

		sound@0 {
			sunxi,cpudai-controller2 = <0x24>;
			sunxi,cpudai-controller0 = <0x22>;
			sunxi,audio-codec = <0x25>;
			compatible = "allwinner,sunxi-ahub-machine";
			sunxi,cpudai-controller1 = <0x23>;
			status = "okay";
			phandle = <0x6b>;
		};

		serial@5000c00 {
			reg-io-width = <0x04>;
			resets = <0x02 0x14>;
			interrupts = <0x00 0x03 0x04>;
			clocks = <0x02 0x45>;
			compatible = "snps,dw-apb-uart";
			status = "disabled";
			reg = <0x5000c00 0x400>;
			phandle = <0x70>;
			reg-shift = <0x02>;
		};

		spi@5010000 {
			pinctrl-names = "default";
			#address-cells = <0x01>;
			pinctrl-0 = <0x30>;
			clock-names = "ahb\0mod";
			resets = <0x02 0x1c>;
			interrupts = <0x00 0x0c 0x04>;
			clocks = <0x02 0x4f 0x02 0x4d>;
			#size-cells = <0x00>;
			dma-names = "rx\0tx";
			compatible = "allwinner,sun50i-h616-spi\0allwinner,sun8i-h3-spi";
			status = "disabled";
			reg = <0x5010000 0x1000>;
			phandle = <0x7b>;
			dmas = <0x21 0x16 0x21 0x16>;
		};

		pinctrl@7022000 {
			clock-names = "apb\0hosc\0losc";
			gpio-controller;
			interrupts = <0x00 0x2b 0x04>;
			clocks = <0x49 0x02 0x0d 0x0e 0x00>;
			compatible = "allwinner,sun50i-h616-r-pinctrl";
			#interrupt-cells = <0x03>;
			reg = <0x7022000 0x400>;
			phandle = <0x98>;
			#gpio-cells = <0x03>;
			interrupt-controller;

			r-rsb-pins {
				function = "s_rsb";
				pins = "PL0\0PL1";
				phandle = <0x4b>;
			};

			r-i2c-pins {
				function = "s_i2c";
				pins = "PL0\0PL1";
				phandle = <0x99>;
			};
		};

		cpudai1-controller@0x05097000 {
			id = <0x01>;
			dma-names = "rx\0tx";
			compatible = "allwinner,sunxi-ahub-cpudai";
			status = "okay";
			reg = <0x5097000 0xadf>;
			phandle = <0x23>;
			dmas = <0x21 0x04 0x21 0x04>;
		};

		usb@5310000 {
			phy-names = "usb";
			resets = <0x02 0x2c 0x02 0x30>;
			interrupts = <0x00 0x1e 0x04>;
			clocks = <0x02 0x6a 0x02 0x6e 0x02 0x64>;
			compatible = "allwinner,sun50i-h616-ehci\0generic-ehci";
			status = "okay";
			phys = <0x38 0x02>;
			reg = <0x5310000 0x100>;
			phandle = <0x88>;
		};

		pwm4@0300a000 {
			pinctrl-names = "default";
			pinctrl-0 = <0x18>;
			compatible = "allwinner,sunxi-pwm4";
			phandle = <0x13>;
		};

		ir@7040000 {
			pinctrl-names = "default";
			pinctrl-0 = <0x4a>;
			clock-names = "apb\0ir";
			resets = <0x49 0x05>;
			interrupts = <0x00 0x6a 0x04>;
			clocks = <0x49 0x09 0x49 0x0b>;
			compatible = "allwinner,sun50i-h616-ir\0allwinner,sun6i-a31-ir";
			status = "disabled";
			reg = <0x7040000 0x400>;
			phandle = <0x9a>;
		};

		ahub_codec@0x05097000 {
			clock-names = "apb\0audio-codec-1x\0audio-codec-4x\0audio-hub";
			resets = <0x02 0x25>;
			clocks = <0x02 0x5f 0x02 0x5b 0x02 0x5c 0x02 0x5e>;
			compatible = "allwinner,sunxi-ahub";
			status = "okay";
			reg = <0x5097000 0xadf>;
			phandle = <0x25>;
		};

		watchdog@30090a0 {
			interrupts = <0x00 0x32 0x04>;
			clocks = <0x0d>;
			compatible = "allwinner,sun50i-h616-wdt\0allwinner,sun6i-a31-wdt";
			status = "okay";
			reg = <0x30090a0 0x20>;
			phandle = <0x5e>;
		};

		usb@5100000 {
			phy-names = "usb";
			resets = <0x02 0x32>;
			interrupts = <0x00 0x19 0x04>;
			clocks = <0x02 0x70>;
			extcon = <0x38 0x00>;
			compatible = "allwinner,sun50i-h616-musb\0allwinner,sun8i-h3-musb";
			status = "okay";
			interrupt-names = "mc";
			phys = <0x38 0x00>;
			reg = <0x5100000 0x400>;
			phandle = <0x83>;
			dr_mode = "peripheral";
		};

		serial@5000000 {
			reg-io-width = <0x04>;
			pinctrl-names = "default";
			pinctrl-0 = <0x27>;
			resets = <0x02 0x11>;
			interrupts = <0x00 0x00 0x04>;
			clocks = <0x02 0x42>;
			compatible = "snps,dw-apb-uart";
			status = "okay";
			reg = <0x5000000 0x400>;
			phandle = <0x6d>;
			reg-shift = <0x02>;
		};
	};

	leds {
		compatible = "gpio-leds";

		gpio_2 {
			function = "wifi_wake";
			default-state = "on";
			gpios = <0x32 0x06 0x0f 0x00>;
		};

		led-1 {
			function = "status";
			color = <0x02>;
			gpio = <0x32 0x07 0x05 0x00>;
			default-state = "on";
			status = "disabled";
		};

		gpio_1 {
			function = "wifi_power";
			default-state = "on";
			gpios = <0x32 0x05 0x06 0x00>;
		};
	};

	psci {
		method = "smc";
		compatible = "arm,psci-0.2";
	};

	gpio_keys {
		compatible = "gpio-keys";
		status = "disabled";

		button_power {
			label = "Power";
			linux,code = <0x74>;
			debounce-interval = <0x64>;
		};
	};

	i2c-gpio {
		#address-cells = <0x01>;
		#size-cells = <0x00>;
		compatible = "i2c-gpio";
		status = "disabled";
		i2c-gpio,delay-us = <0x03>;
		phandle = <0xa4>;
		gpios = <0x32 0x08 0x06 0x00 0x32 0x08 0x04 0x00>;

		bh1750@5c {
			compatible = "rohm,bh1750";
			status = "disabled";
			reg = <0x5c>;
			phandle = <0xa6>;
		};

		ns2009@48 {
			ti,y-plate-ohms = <0x294>;
			i2c,ignore-nak = <0x01>;
			ti,fuzzy = <0x10>;
			compatible = "ti,tsc2007";
			status = "disabled";
			ti,x-plate-ohms = <0x294>;
			reg = <0x48>;
			phandle = <0xa5>;
			ti,fuzzx = <0x20>;
			ti,rt-thr = <0xbb8>;
		};
	};

	timer {
		arm,no-tick-in-suspend;
		interrupts = <0x01 0x0d 0xf04 0x01 0x0e 0xf04 0x01 0x0b 0xf04 0x01 0x0a 0xf04>;
		compatible = "arm,armv8-timer";
	};

	opp-table-cpu {
		opp-shared;
		compatible = "operating-points-v2";
		phandle = <0x03>;

		opp-1200000000 {
			opp-microvolt = <0xea600>;
			opp-hz = <0x00 0x47868c00>;
			clock-latency-ns = <0x3b9b0>;
		};

		opp-480000000 {
			opp-microvolt = <0xc8320>;
			opp-hz = <0x00 0x1c9c3800>;
			clock-latency-ns = <0x3b9b0>;
		};

		opp-1008000000 {
			opp-microvolt = <0xdbba0>;
			opp-hz = <0x00 0x3c14dc00>;
			clock-latency-ns = <0x3b9b0>;
		};

		opp-1512000000 {
			opp-microvolt = <0x10c8e0>;
			opp-hz = <0x00 0x5a1f4a00>;
			clock-latency-ns = <0x3b9b0>;
		};

		opp-792000000 {
			opp-microvolt = <0xd1f60>;
			opp-hz = <0x00 0x2f34f600>;
			clock-latency-ns = <0x3b9b0>;
		};

		opp-600000000 {
			opp-microvolt = <0xc8320>;
			opp-hz = <0x00 0x23c34600>;
			clock-latency-ns = <0x3b9b0>;
		};
	};

	vcc33-wifi {
		regulator-max-microvolt = <0x325aa0>;
		regulator-always-on;
		regulator-min-microvolt = <0x325aa0>;
		regulator-name = "vcc33-wifi";
		compatible = "regulator-fixed";
		phandle = <0x1d>;
		vin-supply = <0x53>;
	};

	aliases {
		ethernet0 = "/soc/ethernet@5030000";
		spi1 = "/soc/spi@5011000";
		serial4 = "/soc/serial@5001000";
		serial0 = "/soc/serial@5000000";
	};

	display-engine {
		allwinner,pipelines = <0x05>;
		compatible = "allwinner,sun50i-h616-display-engine";
		status = "okay";
		phandle = <0x55>;
	};

	chosen {
		linux,initrd-end = <0x00 0x49fff958>;
		bootargs = "root=UUID=6fff31a7-2c07-4302-b461-2b4fd73ec00c rootwait rootfstype=ext4 bootsplash.bootfile=bootsplash.armbian console=ttyS0,115200 console=tty1 consoleblank=0 loglevel=7 ubootpart= usb-storage.quirks=   cgroup_enable=memory swapaccount=1";
		linux,initrd-start = <0x00 0x4972f000>;
		stdout-path = "serial0:115200n8";
	};

	ws2812 {
		pinctrl-names = "default";
		rgb_value = <0x01 0x10000>;
		rgb_cnt = <0x02>;
		compatible = "rgb-ws2812";
		status = "okay";
		phandle = <0xa3>;

		ws2812_pin@0 {
			gpios = <0x32 0x08 0x0f 0x01>;
		};
	};

	ac200_clk {
		#clock-cells = <0x00>;
		clock-frequency = <0x1e8480>;
		compatible = "pwm-clock";
		status = "okay";
		phandle = <0x2d>;
		pwms = <0x54 0x05 0x1f4 0x01>;
	};

	vcc-wifi-io {
		regulator-max-microvolt = <0x1b7740>;
		regulator-always-on;
		regulator-min-microvolt = <0x1b7740>;
		regulator-name = "vcc-wifi-io";
		compatible = "regulator-fixed";
		phandle = <0x1e>;
		vin-supply = <0x1d>;
	};

	pmu {
		interrupt-affinity = <0x06 0x07 0x08 0x09>;
		interrupts = <0x00 0x8c 0x04 0x00 0x8d 0x04 0x00 0x8e 0x04 0x00 0x8f 0x04>;
		compatible = "arm,cortex-a53-pmu";
	};

	cpus {
		#address-cells = <0x01>;
		#size-cells = <0x00>;

		cpu@1 {
			clocks = <0x02 0x15>;
			device_type = "cpu";
			compatible = "arm,cortex-a53";
			reg = <0x01>;
			enable-method = "psci";
			phandle = <0x07>;
			operating-points-v2 = <0x03>;
			clock-latency-ns = <0x3b9b0>;
			#cooling-cells = <0x02>;
		};

		cpu@2 {
			clocks = <0x02 0x15>;
			device_type = "cpu";
			compatible = "arm,cortex-a53";
			reg = <0x02>;
			enable-method = "psci";
			phandle = <0x08>;
			operating-points-v2 = <0x03>;
			clock-latency-ns = <0x3b9b0>;
			#cooling-cells = <0x02>;
		};

		cpu@0 {
			cpu-supply = <0x04>;
			clocks = <0x02 0x15>;
			device_type = "cpu";
			compatible = "arm,cortex-a53";
			status = "okay";
			reg = <0x00>;
			enable-method = "psci";
			phandle = <0x06>;
			operating-points-v2 = <0x03>;
			clock-latency-ns = <0x3b9b0>;
			#cooling-cells = <0x02>;
		};

		cpu@3 {
			clocks = <0x02 0x15>;
			device_type = "cpu";
			compatible = "arm,cortex-a53";
			reg = <0x03>;
			enable-method = "psci";
			phandle = <0x09>;
			operating-points-v2 = <0x03>;
			clock-latency-ns = <0x3b9b0>;
			#cooling-cells = <0x02>;
		};
	};

	__symbols__ {
		i2c3 = "/soc/i2c@5002c00";
		pwm = "/soc/pwm@300a000";
		syscon = "/soc/syscon@3000000";
		ohci2 = "/soc/usb@5310400";
		ths_calibration = "/soc/efuse@3006000/thermal-sensor-calibration@14";
		spi1_cs_pin = "/soc/pinctrl@300b000/spi1-cs-pin";
		cpu_crit = "/thermal-zones/cpu-thermal/trips/cpu_crit";
		wifi_pwrseq = "/wifi-pwrseq";
		emac1 = "/soc/ethernet@5030000";
		ir = "/soc/ir@7040000";
		r_rsb_pins = "/soc/pinctrl@7022000/r-rsb-pins";
		secmon_reserved = "/reserved-memory/secmon@40000000";
		ephy_calibration = "/soc/efuse@3006000/ephy-calibration@2c";
		i2c1 = "/soc/i2c@5002400";
		r_i2c_pins = "/soc/pinctrl@7022000/r-i2c-pins";
		ohci0 = "/soc/usb@5101400";
		uart4_ph_pins = "/soc/pinctrl@300b000/uart4-ph-pins";
		i2c4_pins = "/soc/pinctrl@300b000/i2c4-pins";
		hdmi_con_in = "/connector/port/endpoint";
		display_clocks = "/soc/bus@1000000/clock@8000";
		uart2_rts_cts_pins = "/soc/pinctrl@300b000/uart2-rts-cts-pins";
		gpu = "/soc/gpu@0x01800000";
		spi0 = "/soc/spi@5010000";
		light = "/i2c-gpio/bh1750@5c";
		ac200_codec = "/soc/i2c@5002c00/mfd@10/codec";
		pwm4_pin = "/soc/pinctrl@300b000/pwm4-pin";
		rmii_pins = "/soc/pinctrl@300b000/rmii-pins";
		pwm5 = "/soc/pwm5@0300a000";
		mmc1 = "/soc/mmc@4021000";
		r_ccu = "/soc/clock@7010000";
		hdmi_phy = "/soc/hdmi-phy@6010000";
		ahub_cpudai2 = "/soc/cpudai2-controller@0x05097000";
		uart4 = "/soc/serial@5001000";
		tcon_top_hdmi_in = "/soc/tcon-top@6510000/ports/port@4";
		mmc2_pins = "/soc/pinctrl@300b000/mmc2-pins";
		reg_usb1_vbus = "/usb1-vbus";
		twi3_pins = "/soc/pinctrl@300b000/twi3-pins";
		dma = "/soc/dma-controller@3002000";
		i2c3_pins = "/soc/pinctrl@300b000/i2c3-pins";
		ccu = "/soc/clock@3001000";
		pwm3 = "/soc/pwm3@0300a000";
		tcon_tv = "/soc/lcd-controller@6515000";
		tcon_top_hdmi_out = "/soc/tcon-top@6510000/ports/port@5";
		ahub_cpudai0 = "/soc/cpudai0-controller@0x05097000";
		sram_a2 = "/soc/syscon@3000000/sram@100000";
		cpu3 = "/cpus/cpu@3";
		uart2 = "/soc/serial@5000800";
		ir_rx_pin = "/soc/pinctrl@300b000/ir-rx-pin";
		rmii_phy = "/soc/ethernet@5030000/mdio/ethernet-phy@1";
		tcon_top_mixer0_in = "/soc/tcon-top@6510000/ports/port@0";
		gic = "/soc/interrupt-controller@3021000";
		cpu_very_hot = "/thermal-zones/cpu-thermal/trips/cpu_very_hot";
		tft_35 = "/soc/spi@5011000/st7796@1";
		pwm1 = "/soc/pwm1@0300a000";
		mmc1_pins = "/soc/pinctrl@300b000/mmc1-pins";
		can0_pin_irq = "/soc/pinctrl@300b000/can0_pin_irq";
		ac200_ephy = "/soc/i2c@5002c00/mfd@10/phy";
		mdio1 = "/soc/ethernet@5030000/mdio";
		pwm1_pin = "/soc/pinctrl@300b000/pwm1-pin";
		gpu_opp_table = "/opp-table-1";
		mixer0 = "/soc/bus@1000000/mixer@100000";
		cpu1 = "/cpus/cpu@1";
		scpi_sram = "/soc/syscon@3000000/sram@100000/scpi-sram@17c00";
		uart0 = "/soc/serial@5000000";
		ehci2 = "/soc/usb@5310000";
		dump_reg = "/soc/dump_reg@20000";
		mixer0_out = "/soc/bus@1000000/mixer@100000/ports/port@1";
		hdmi_audio = "/soc/hdmi-audio@1";
		r_rsb = "/soc/rsb@7083000";
		reg_dcdc2 = "/soc/i2c@7081400/pmic@36/regulators/dcdc2";
		i2c2_pins = "/soc/pinctrl@300b000/i2c2-pins";
		i2c4 = "/soc/i2c@5003000";
		pwm5_pin = "/soc/pinctrl@300b000/pwm5-pin";
		ac200_x = "/soc/i2c@5002c00/mfd@10";
		ohci3 = "/soc/usb@5311400";
		sndahub = "/soc/sound@0";
		cpu_hot_pre = "/thermal-zones/cpu-thermal/trips/cpu_hot_pre";
		addr_mgt = "/soc/addr-mgt";
		cpu_opp_table = "/opp-table-cpu";
		cpu_speed_grade = "/soc/efuse@3006000/cpu-speed-grade@00";
		ehci0 = "/soc/usb@5101000";
		reg_vcc_wifi_io = "/vcc-wifi-io";
		hdmi_out = "/soc/hdmi@6000000/ports/port@1";
		tcon_top_hdmi_in_tcon_tv = "/soc/tcon-top@6510000/ports/port@4/endpoint@0";
		i2c_gpio = "/i2c-gpio";
		i2c2 = "/soc/i2c@5002800";
		tcon_top = "/soc/tcon-top@6510000";
		ohci1 = "/soc/usb@5200400";
		mmc0_pins = "/soc/pinctrl@300b000/mmc0-pins";
		cpu_hot = "/thermal-zones/cpu-thermal/trips/cpu_hot";
		sram_c = "/soc/syscon@3000000/sram@28000";
		emac0 = "/soc/ethernet@5020000";
		reg_dldo1 = "/soc/i2c@7081400/pmic@36/regulators/ldo2";
		i2c1_pins = "/soc/pinctrl@300b000/i2c1-pins";
		tft_tp = "/i2c-gpio/ns2009@48";
		spi1 = "/soc/spi@5011000";
		hdmi_out_con = "/soc/hdmi@6000000/ports/port@1/endpoint";
		usbphy = "/soc/phy@5100400";
		tcon_top_mixer0_out = "/soc/tcon-top@6510000/ports/port@1";
		tcon_top_mixer0_out_tcon_tv = "/soc/tcon-top@6510000/ports/port@1/endpoint@2";
		de3_sram = "/soc/syscon@3000000/sram@28000/sram-section@0";
		i2c0 = "/soc/i2c@5002000";
		mmc2 = "/soc/mmc@4022000";
		spi1_pins = "/soc/pinctrl@300b000/spi1-pins";
		ahub_codec = "/soc/ahub_codec@0x05097000";
		pwm2_pin = "/soc/pinctrl@300b000/pwm2-pin";
		usbotg = "/soc/usb@5100000";
		i2s3_pins = "/soc/pinctrl@300b000/i2s3-pins";
		uart5 = "/soc/serial@5001400";
		uart5_ph_pins = "/soc/pinctrl@300b000/uart5-ph-pins";
		codec = "/soc/codec@05096000";
		osc24M = "/osc24M_clk";
		hdmi_in_tcon_top = "/soc/hdmi@6000000/ports/port@0/endpoint";
		reg_vcc5v = "/vcc5v";
		tcon_tv_in = "/soc/lcd-controller@6515000/ports/port@0";
		pwm4 = "/soc/pwm4@0300a000";
		mmc0 = "/soc/mmc@4020000";
		ac200_pwm_clk = "/ac200_clk";
		tcon_top_mixer0_in_mixer0 = "/soc/tcon-top@6510000/ports/port@0/endpoint@0";
		tcon_tv_out_tcon_top = "/soc/lcd-controller@6515000/ports/port@1/endpoint@1";
		i2c0_pins = "/soc/pinctrl@300b000/i2c0-pins";
		tcon_tv_out = "/soc/lcd-controller@6515000/ports/port@1";
		ahub_cpudai1 = "/soc/cpudai1-controller@0x05097000";
		axp1530 = "/soc/i2c@7081400/pmic@36";
		r_pio = "/soc/pinctrl@7022000";
		ws2812 = "/ws2812";
		can = "/soc/spi@5011000/mcp2515@0";
		uart3 = "/soc/serial@5000c00";
		tcon_top_hdmi_out_hdmi = "/soc/tcon-top@6510000/ports/port@5/endpoint";
		sram_c1 = "/soc/syscon@3000000/sram@1a00000";
		uart1_pins = "/soc/pinctrl@300b000/uart1-pins";
		spi0_pins = "/soc/pinctrl@300b000/spi0-pins";
		reg_aldo1 = "/soc/i2c@7081400/pmic@36/regulators/ldo1";
		mixer0_out_tcon_top_mixer0 = "/soc/bus@1000000/mixer@100000/ports/port@1/endpoint";
		tcon_tv_in_tcon_top_mixer0 = "/soc/lcd-controller@6515000/ports/port@0/endpoint";
		uart1_rts_cts_pins = "/soc/pinctrl@300b000/uart1-rts-cts-pins";
		pwm2 = "/soc/pwm2@0300a000";
		ve_sram = "/soc/syscon@3000000/sram@1a00000/sram-section@0";
		pio = "/soc/pinctrl@300b000";
		reg_vcc33_wifi = "/vcc33-wifi";
		uart0_ph_pins = "/soc/pinctrl@300b000/uart0-ph-pins";
		standby_param = "/soc/i2c@7081400/pmic@36/standby_param";
		cpu2 = "/cpus/cpu@2";
		ths = "/soc/thermal-sensor@5070400";
		uart1 = "/soc/serial@5000400";
		ehci3 = "/soc/usb@5311000";
		hdmi = "/soc/hdmi@6000000";
		spidev1_1 = "/soc/spi@5011000/spidev@1";
		r_i2c = "/soc/i2c@7081400";
		hdmi_in = "/soc/hdmi@6000000/ports/port@0";
		reg_dcdc3 = "/soc/i2c@7081400/pmic@36/regulators/dcdc3";
		ext_rgmii_pins = "/soc/pinctrl@300b000/rgmii-pins";
		ahub_i2s3 = "/soc/ahub-i2s3@0x05097000";
		mcp2515_clock = "/mcp2515_clock";
		de = "/display-engine";
		pwm3_pin = "/soc/pinctrl@300b000/pwm3-pin";
		pwm0 = "/soc/pwm0@0300a000";
		cpu_warm = "/thermal-zones/cpu-thermal/trips/cpu_warm";
		rtc = "/soc/rtc@7000000";
		watchdog = "/soc/watchdog@30090a0";
		mdio0 = "/soc/ethernet@5020000/mdio";
		cpu0 = "/cpus/cpu@0";
		sid = "/soc/efuse@3006000";
		ehci1 = "/soc/usb@5200000";
		reg_dcdc1 = "/soc/i2c@7081400/pmic@36/regulators/dcdc1";
		ahub_i2s1 = "/soc/ahub-i2s1@0x05097000";
		uart2_ph_pins = "/soc/pinctrl@300b000/uart2-ph-pins";
	};

	reserved-memory {
		#address-cells = <0x02>;
		#size-cells = <0x02>;
		ranges;

		secmon@40000000 {
			reg = <0x00 0x40000000 0x00 0x80000>;
			phandle = <0x56>;
			no-map;
		};
	};

	mcp2515_clock {
		#clock-cells = <0x00>;
		clock-frequency = <0xb71b00>;
		compatible = "fixed-clock";
		phandle = <0x33>;
	};

	osc24M_clk {
		clock-output-names = "osc24M";
		#clock-cells = <0x00>;
		clock-frequency = <0x16e3600>;
		compatible = "fixed-clock";
		phandle = <0x0d>;
	};

	memory {
		device_type = "memory";
		reg = <0x00 0x40000000 0x00 0x40000000>;
	};
};
